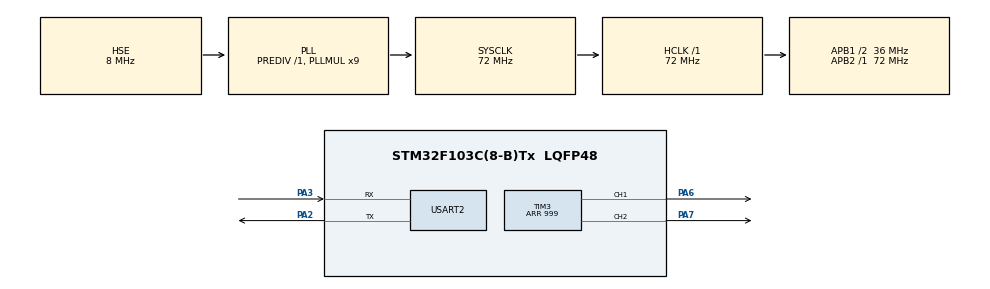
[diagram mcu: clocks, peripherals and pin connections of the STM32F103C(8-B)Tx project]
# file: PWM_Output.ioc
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Mcu.Family=STM32F1
Mcu.Name=STM32F103C(8-B)Tx
Mcu.Package=LQFP48
NVIC.PriorityGroup=NVIC_PRIORITYGROUP_4
NVIC.USART2_IRQn=true\:0\:0\:false\:false\:true\:true\:true
PA13.Mode=Serial_Wire
PA13.Signal=SYS_JTMS-SWDIO
PA14.Mode=Serial_Wire
PA14.Signal=SYS_JTCK-SWCLK
PA2.Mode=Asynchronous
PA2.Signal=USART2_TX
PA3.Mode=Asynchronous
PA3.Signal=USART2_RX
PA6.Signal=S_TIM3_CH1
PA7.Signal=S_TIM3_CH2
PD0-OSC_IN.Mode=HSE-External-Oscillator
PD0-OSC_IN.Signal=RCC_OSC_IN
PD1-OSC_OUT.Mode=HSE-External-Oscillator
PD1-OSC_OUT.Signal=RCC_OSC_OUT
ProjectManager.HeapSize=0x200
ProjectManager.StackSize=0x400
ProjectManager.TargetToolchain=MDK-ARM V5.27
RCC.AHBFreq_Value=72000000
RCC.APB1CLKDivider=RCC_HCLK_DIV2
RCC.APB1Freq_Value=36000000
RCC.APB1TimFreq_Value=72000000
RCC.APB2Freq_Value=72000000
RCC.APB2TimFreq_Value=72000000
RCC.HCLKFreq_Value=72000000
RCC.PLLMUL=RCC_PLL_MUL9
RCC.PLLSourceVirtual=RCC_PLLSOURCE_HSE
RCC.SYSCLKFreq_VALUE=72000000
RCC.SYSCLKSource=RCC_SYSCLKSOURCE_PLLCLK
RCC.USBFreq_Value=72000000
SH.S_TIM3_CH1.0=TIM3_CH1,PWM Generation1 CH1
SH.S_TIM3_CH2.0=TIM3_CH2,PWM Generation2 CH2
TIM3.Channel-PWM\ Generation1\ CH1=TIM_CHANNEL_1
TIM3.Channel-PWM\ Generation2\ CH2=TIM_CHANNEL_2
TIM3.Period=999
TIM3.Pulse-PWM\ Generation1\ CH1=300
TIM3.Pulse-PWM\ Generation2\ CH2=400
USART2.VirtualMode=VM_ASYNC
VP_TIM3_VS_ClockSourceINT.Mode=Internal
board=custom

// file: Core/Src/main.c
/* USER CODE BEGIN Header */
/**
  ******************************************************************************
  * @file           : main.c
  * @brief          : Main program body
  ******************************************************************************
  * @attention
  *
  * <h2><center>&copy; Copyright (c) 2021 STMicroelectronics.
  * All rights reserved.</center></h2>
  *
  * This software component is licensed by ST under BSD 3-Clause license,
  * the "License"; You may not use this file except in compliance with the
  * License. You may obtain a copy of the License at:
  *                        opensource.org/licenses/BSD-3-Clause
  *
  ******************************************************************************
  */
/* USER CODE END Header */
#include "main.h"
#include "tim.h"
#include "usart.h"
#include "gpio.h"

/* USER CODE BEGIN PD */
#define MAX_LENGTH 100
//extern TIM_OC_InitTypeDef sConfigOC;
/* USER CODE END PD */

/* USER CODE BEGIN PV */
uint8_t recieve[MAX_LENGTH];
uint8_t temp;
uint8_t cnt=0;
uint16_t psc=200;    // wait for uart input
uint16_t crr1=500;
/* USEuint8_t arr1R CODE END PV */

void SystemClock_Config(void);

int main(void)
{

  /* MCU Configuration--------------------------------------------------------*/

  /* Reset of all peripherals, Initializes the Flash interface and the Systick. */
  HAL_Init();

  /* Configure the system clock */
  SystemClock_Config();

  /* Initialize all configured peripherals */
  MX_GPIO_Init();
	MX_TIM3_Init();
	MX_USART2_UART_Init();
  /* USER CODE BEGIN 2 */
//	HAL_UART_RxCpltCallback(&huart2);
// __HAL_UART_ENABLE_IT(&huart2,ENABLE);
 HAL_UART_RxCpltCallback(&huart2);
  HAL_TIM_PWM_Start(&htim3,TIM_CHANNEL_2);
	HAL_TIM_PWM_Start(&htim3,TIM_CHANNEL_1);
	/* USER CODE END 2 */

  /* Infinite loop */
  while (1)
  {

    /* USER CODE BEGIN 3 */
			//psc= (recieve[6]-48)*100+(recieve[7]-48)*10+(recieve[8]-48);
	    //crr1 = (recieve[23]-48)*100+(recieve[24]-48)*10;
       htim3.Init.Prescaler = 72000/psc-1;
		   //sConfigOC.Pulse = crr1;
  }
  /* USER CODE END 3 */
}

void SystemClock_Config(void)
{
  RCC_OscInitTypeDef RCC_OscInitStruct = {0};
  RCC_ClkInitTypeDef RCC_ClkInitStruct = {0};

  /** Initializes the RCC Oscillators according to the specified parameters
  * in the RCC_OscInitTypeDef structure.
  */
  RCC_OscInitStruct.OscillatorType = RCC_OSCILLATORTYPE_HSE;
  RCC_OscInitStruct.HSEState = RCC_HSE_ON;
  RCC_OscInitStruct.HSEPredivValue = RCC_HSE_PREDIV_DIV1;
  RCC_OscInitStruct.HSIState = RCC_HSI_ON;
  RCC_OscInitStruct.PLL.PLLState = RCC_PLL_ON;
  RCC_OscInitStruct.PLL.PLLSource = RCC_PLLSOURCE_HSE;
  RCC_OscInitStruct.PLL.PLLMUL = RCC_PLL_MUL9;
  if (HAL_RCC_OscConfig(&RCC_OscInitStruct) != HAL_OK)
  {
    Error_Handler();
  }
  /** Initializes the CPU, AHB and APB buses clocks
  */
  RCC_ClkInitStruct.ClockType = RCC_CLOCKTYPE_HCLK|RCC_CLOCKTYPE_SYSCLK
                              |RCC_CLOCKTYPE_PCLK1|RCC_CLOCKTYPE_PCLK2;
  RCC_ClkInitStruct.SYSCLKSource = RCC_SYSCLKSOURCE_PLLCLK;
  RCC_ClkInitStruct.AHBCLKDivider = RCC_SYSCLK_DIV1;
  RCC_ClkInitStruct.APB1CLKDivider = RCC_HCLK_DIV2;
  RCC_ClkInitStruct.APB2CLKDivider = RCC_HCLK_DIV1;

  if (HAL_RCC_ClockConfig(&RCC_ClkInitStruct, FLASH_LATENCY_2) != HAL_OK)
  {
    Error_Handler();
  }
}

/* USER CODE BEGIN 4 */
void HAL_UART_RxCpltCallback(UART_HandleTypeDef *huart)
{
	if (temp!='-')
	{
		HAL_UART_Receive_IT(&huart2,&temp,1);
		recieve[cnt]=temp;
		cnt++;
	}
  psc= (recieve[6]-48)*100+(recieve[7]-48)*10+(recieve[8]-48);
	crr1 = (recieve[23]-48)*100+(recieve[24]-48)*10;
//	else
//	{
//		HAL_UART_Transmit(&huart2,recieve,cnt,HAL_MAX_DELAY);
//		cnt = 0;
//		HAL_UART_Receive_IT(&huart2,&temp,1);
//	}
}
/* USER CODE END 4 */

void Error_Handler(void)
{
  __disable_irq();
  while (1)
  {
  }
}

/************************ (C) COPYRIGHT STMicroelectronics *****END OF FILE****/
